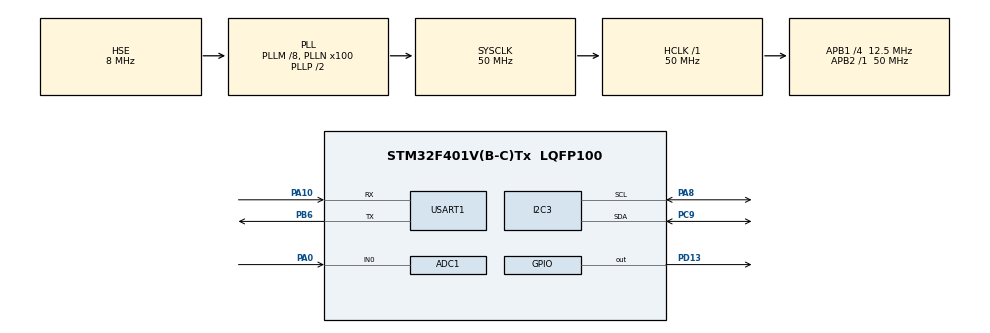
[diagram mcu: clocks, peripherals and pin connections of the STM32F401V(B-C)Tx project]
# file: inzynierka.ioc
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ADC1.Channel-0\#ChannelRegularConversion=ADC_CHANNEL_0
ADC1.NbrOfConversionFlag=1
ADC1.Rank-0\#ChannelRegularConversion=1
ADC1.SamplingTime-0\#ChannelRegularConversion=ADC_SAMPLETIME_3CYCLES
ADC1.master=1
FREERTOS.Tasks01=defaultTask,0,128,StartDefaultTask,Default,NULL
Mcu.Family=STM32F4
Mcu.Name=STM32F401V(B-C)Tx
Mcu.Package=LQFP100
NVIC.PriorityGroup=NVIC_PRIORITYGROUP_4
PA0-WKUP.Signal=ADCx_IN0
PA10.Mode=Asynchronous
PA10.Signal=USART1_RX
PA8.Mode=SMBus-two-wire-Interface
PA8.Signal=I2C3_SCL
PB6.Mode=Asynchronous
PB6.Signal=USART1_TX
PC9.Mode=SMBus-two-wire-Interface
PC9.Signal=I2C3_SDA
PD13.GPIO_ModeDefaultOutputPP=GPIO_MODE_OUTPUT_PP
PD13.GPIO_PuPd=GPIO_PULLUP
PD13.PinState=GPIO_PIN_SET
PD13.Signal=GPIO_Output
PH0\ -\ OSC_IN.Mode=HSE-External-Oscillator
PH0\ -\ OSC_IN.Signal=RCC_OSC_IN
PH1\ -\ OSC_OUT.Mode=HSE-External-Oscillator
PH1\ -\ OSC_OUT.Signal=RCC_OSC_OUT
ProjectManager.HeapSize=0x200
ProjectManager.StackSize=0x400
ProjectManager.TargetToolchain=STM32CubeIDE
RCC.48MHZClocksFreq_Value=14285714.285714285
RCC.AHBFreq_Value=50000000
RCC.APB1CLKDivider=RCC_HCLK_DIV4
RCC.APB1Freq_Value=12500000
RCC.APB1TimFreq_Value=25000000
RCC.APB2Freq_Value=50000000
RCC.APB2TimFreq_Value=50000000
RCC.CortexFreq_Value=50000000
RCC.HCLKFreq_Value=50000000
RCC.HSE_VALUE=8000000
RCC.HSI_VALUE=16000000
RCC.LSE_VALUE=32768
RCC.PLLM=8
RCC.PLLN=100
RCC.PLLQ=7
RCC.PLLSourceVirtual=RCC_PLLSOURCE_HSE
RCC.SYSCLKFreq_VALUE=50000000
RCC.SYSCLKSource=RCC_SYSCLKSOURCE_PLLCLK
RCC.VCOOutputFreq_Value=100000000
SH.ADCx_IN0.0=ADC1_IN0,IN0
USART1.VirtualMode=VM_ASYNC
VP_FREERTOS_VS_CMSIS_V1.Mode=CMSIS_V1
board=STM32F401C-DISCO

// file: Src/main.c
/* USER CODE BEGIN Header */
/**
  ******************************************************************************
  * @file           : main.c
  * @brief          : Main program body
  ******************************************************************************
  * @attention
  *
  * <h2><center>&copy; Copyright (c) 2019 STMicroelectronics.
  * All rights reserved.</center></h2>
  *
  * This software component is licensed by ST under BSD 3-Clause license,
  * the "License"; You may not use this file except in compliance with the
  * License. You may obtain a copy of the License at:
  *                        opensource.org/licenses/BSD-3-Clause
  *
  ******************************************************************************
  */

#define CFG_CLI_STACK_DEPTH 	600
#define CFG_EVENT_STACK_DEPTH		400

#include "main.h"

#include <stdio.h>
#include <stdlib.h>
#include <assert.h>
#include <string.h>

#include "flash.h"
#include "ring_buffer.h"
#include "cmsis_os.h"
#include "i2c.h"
#include "usart.h"
#include "adc.h"
#include "gpio.h"
#include "cli.h"
#include "event.h"

void SystemClock_Config(void);
void MX_FREERTOS_Init(void);

static void init_task(TaskFunction_t task_cb, const char* task_name, const uint16_t stack_depth, void* const params, UBaseType_t priority, TaskHandle_t* const task_handle)
{

	char* s_pass = " inicialization passed!\n";
	char* s_fail = " inicialization failed!\n";
	char *result = malloc(strlen(task_name) + strlen(s_pass) + 1);

	if(xTaskCreate(task_cb, task_name, stack_depth, params, priority, task_handle) == pdPASS)
	{
	    strcpy(result, task_name);
	    strcat(result, s_pass);
		cli_send_string(result);
	}
	else
	{
	    strcpy(result, task_name);
	    strcat(result, s_fail);
		cli_send_string(result);
	}
    free(result);
}

void cli_task(void * args)
{
//	TickType_t start = 0;
	cli_init();
	while(1)
	{
		cli_process();
//		vTaskDelayUntil(&start, 1);
	}
}

void event_task(void *args)
{
	TickType_t start = 0;
	event_init();
	while(1)
	{
		event_process();
		vTaskDelayUntil(&start, 100);
	}
}

int main(void)
{
  HAL_Init();
  SystemClock_Config();

  MX_GPIO_Init();
  MX_I2C3_Init();
  MX_USART1_UART_Init();
  MX_ADC1_Init();

  init_task(cli_task, "CLI task", CFG_CLI_STACK_DEPTH, NULL, 4, NULL);
  init_task(event_task, "Event task", CFG_EVENT_STACK_DEPTH, NULL, 4, NULL);

  /* Start scheduler */
  osKernelStart();

  /* We should never get here as control is now taken by the scheduler */
  while (1)
  {
	  /* Infinite loop. */
  }

}

void SystemClock_Config(void)
{
  RCC_OscInitTypeDef RCC_OscInitStruct = {0};
  RCC_ClkInitTypeDef RCC_ClkInitStruct = {0};

  /** Configure the main internal regulator output voltage
  */
  __HAL_RCC_PWR_CLK_ENABLE();
  __HAL_PWR_VOLTAGESCALING_CONFIG(PWR_REGULATOR_VOLTAGE_SCALE2);
  /** Initializes the CPU, AHB and APB busses clocks
  */
  RCC_OscInitStruct.OscillatorType = RCC_OSCILLATORTYPE_HSE;
  RCC_OscInitStruct.HSEState = RCC_HSE_ON;
  RCC_OscInitStruct.PLL.PLLState = RCC_PLL_ON;
  RCC_OscInitStruct.PLL.PLLSource = RCC_PLLSOURCE_HSE;
  RCC_OscInitStruct.PLL.PLLM = 8;
  RCC_OscInitStruct.PLL.PLLN = 100;
  RCC_OscInitStruct.PLL.PLLP = RCC_PLLP_DIV2;
  RCC_OscInitStruct.PLL.PLLQ = 7;
  if (HAL_RCC_OscConfig(&RCC_OscInitStruct) != HAL_OK)
  {
    Error_Handler();
  }
  /** Initializes the CPU, AHB and APB busses clocks
  */
  RCC_ClkInitStruct.ClockType = RCC_CLOCKTYPE_HCLK|RCC_CLOCKTYPE_SYSCLK
                              |RCC_CLOCKTYPE_PCLK1|RCC_CLOCKTYPE_PCLK2;
  RCC_ClkInitStruct.SYSCLKSource = RCC_SYSCLKSOURCE_PLLCLK;
  RCC_ClkInitStruct.AHBCLKDivider = RCC_SYSCLK_DIV1;
  RCC_ClkInitStruct.APB1CLKDivider = RCC_HCLK_DIV4;
  RCC_ClkInitStruct.APB2CLKDivider = RCC_HCLK_DIV1;

  if (HAL_RCC_ClockConfig(&RCC_ClkInitStruct, FLASH_LATENCY_1) != HAL_OK)
  {
    Error_Handler();
  }
}

void Error_Handler(void)
{
  /* USER CODE BEGIN Error_Handler_Debug */
  /* User can add his own implementation to report the HAL error return state */
	cli_send_string("ERROR HANDLER!\n\r");
  /* USER CODE END Error_Handler_Debug */
}

/************************ (C) COPYRIGHT STMicroelectronics *****END OF FILE****/

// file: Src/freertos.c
/* USER CODE BEGIN Header */
/**
  ******************************************************************************
  * File Name          : freertos.c
  * Description        : Code for freertos applications
  ******************************************************************************
  * @attention
  *
  * <h2><center>&copy; Copyright (c) 2019 STMicroelectronics.
  * All rights reserved.</center></h2>
  *
  * This software component is licensed by ST under Ultimate Liberty license
  * SLA0044, the "License"; You may not use this file except in compliance with
  * the License. You may obtain a copy of the License at:
  *                             www.st.com/SLA0044
  *
  ******************************************************************************
  */
/* USER CODE END Header */

#include "FreeRTOS.h"
#include "task.h"
#include "main.h"
#include "cmsis_os.h"

osThreadId defaultTaskHandle;

void StartDefaultTask(void const * argument);

void MX_FREERTOS_Init(void); /* (MISRA C 2004 rule 8.1) */

/* GetIdleTaskMemory prototype (linked to static allocation support) */
void vApplicationGetIdleTaskMemory( StaticTask_t **ppxIdleTaskTCBBuffer, StackType_t **ppxIdleTaskStackBuffer, uint32_t *pulIdleTaskStackSize );

/* USER CODE BEGIN GET_IDLE_TASK_MEMORY */
static StaticTask_t xIdleTaskTCBBuffer;
static StackType_t xIdleStack[configMINIMAL_STACK_SIZE];

void vApplicationGetIdleTaskMemory( StaticTask_t **ppxIdleTaskTCBBuffer, StackType_t **ppxIdleTaskStackBuffer, uint32_t *pulIdleTaskStackSize )
{
  *ppxIdleTaskTCBBuffer = &xIdleTaskTCBBuffer;
  *ppxIdleTaskStackBuffer = &xIdleStack[0];
  *pulIdleTaskStackSize = configMINIMAL_STACK_SIZE;
  /* place for user code */
}
/* USER CODE END GET_IDLE_TASK_MEMORY */

void MX_FREERTOS_Init(void) {

  /* Create the thread(s) */
  /* definition and creation of defaultTask */
  osThreadDef(defaultTask, StartDefaultTask, osPriorityNormal, 0, 128);
  defaultTaskHandle = osThreadCreate(osThread(defaultTask), NULL);

}

void StartDefaultTask(void const * argument)
{

  for(;;)
  {
    osDelay(1);
  }
}

/************************ (C) COPYRIGHT STMicroelectronics *****END OF FILE****/
